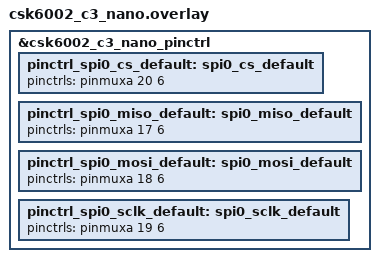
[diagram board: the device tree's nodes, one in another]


&csk6002_c3_nano_pinctrl{
            /* SPIC alternate function */
            pinctrl_spi0_cs_default: spi0_cs_default{
                    pinctrls = <&pinmuxa 20 6>;
            };

            pinctrl_spi0_miso_default: spi0_miso_default{
                    pinctrls = <&pinmuxa 17 6>;
            };

            pinctrl_spi0_mosi_default: spi0_mosi_default{
                    pinctrls = <&pinmuxa 18 6>;
            };

            pinctrl_spi0_sclk_default: spi0_sclk_default{
                    pinctrls = <&pinmuxa 19 6>;
            };
            
};
